# LPC18xx register map
File version: 18
Registers are 32-bit, read-write, reset 0x0 unless marked. A register's access mark holds for its fields unless they carry their own. Offsets are from the block's base; [hi:lo] are bit positions; 'fields as' and 'values as' point back to an identical list.

## I2S0 — Product name title=UM10430 Chapter title=LPC18xx I2S interface Modification date=1/14/2011 Major revision=0 Minor revision=7
Base 0x400A2000
Same registers: I2S1 0x400A3000
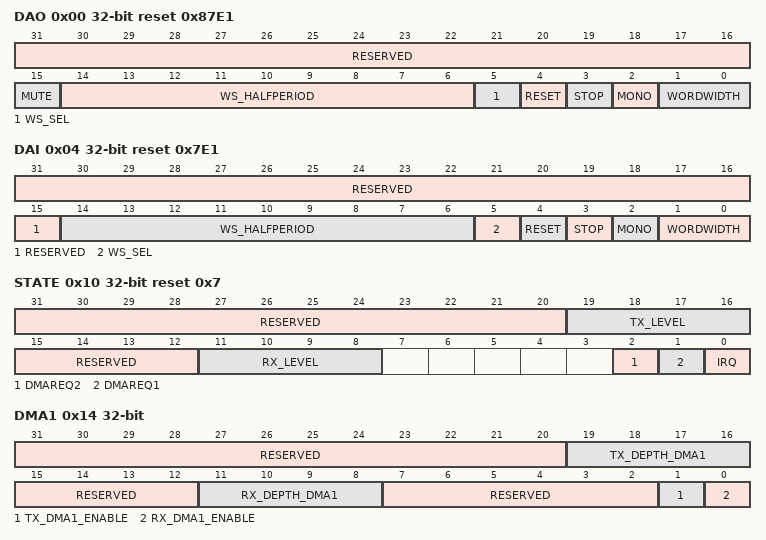
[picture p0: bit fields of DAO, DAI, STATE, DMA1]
0x00 DAO reset 0x87E1 — I2S Digital Audio Output Register. Contains control bits for the I2S transmit channel.
  [31:16] RESERVED — Reserved, user software should not write ones to reserved bits. The value read from a reserved bit is not defined.
  [15] MUTE — When 1, the transmit channel sends only zeroes.
  [14:6] WS_HALFPERIOD — Word select half period minus 1, i.e. WS 64clk period -> ws_halfperiod = 31.
  [5] WS_SEL — When 0, the interface is in master mode. When 1, the interface is in slave mode. See Section 34.7.2 for a summary of useful combinations for this bit with TXMODE.
  [4] RESET — When 1, asynchronously resets the transmit channel and FIFO.
  [3] STOP — When 1, disables accesses on FIFOs, places the transmit channel in mute mode.
  [2] MONO — When 1, data is of monaural format. When 0, the data is in stereo format.
  [1:0] WORDWIDTH — Selects the number of bytes in data as follows:
    0=8_BIT_DATA; 1=16_BIT_DATA; 2=RESERVED,_DO_NOT_USE (Reserved, do not use this setting); 3=32_BIT_DATA
0x04 DAI reset 0x7E1 — I2S Digital Audio Input Register. Contains control bits for the I2S receive channel.
  [31:15] RESERVED — Reserved, user software should not write ones to reserved bits. The value read from a reserved bit is not defined.
  [14:6] WS_HALFPERIOD — Word select half period minus 1, i.e. WS 64clk period -> ws_halfperiod = 31.
  [5] WS_SEL — When 0, the interface is in master mode. When 1, the interface is in slave mode. See Section 34.7.2 for a summary of useful combinations for this bit with RXMODE.
  [4] RESET — When 1, asynchronously reset the transmit channel and FIFO.
  [3] STOP — When 1, disables accesses on FIFOs, places the transmit channel in mute mode.
  [2] MONO — When 1, data is of monaural format. When 0, the data is in stereo format.
  [1:0] WORDWIDTH — Selects the number of bytes in data as follows:
    values as DAO.WORDWIDTH
0x08 TXFIFO wo — I2S Transmit FIFO. Access register for the 8 x 32-bit transmitter FIFO.
  [31:0] I2STXFIFO — 8 x 32-bit transmit FIFO.
0x0C RXFIFO ro — I2S Receive FIFO. Access register for the 8 x 32-bit receiver FIFO.
  [31:0] I2SRXFIFO — 8 x 32-bit transmit FIFO.
0x10 STATE ro reset 0x7 — I2S Status Feedback Register. Contains status information about the I2S interface.
  [31:20] RESERVED — Reserved, user software should not write ones to reserved bits. The value read from a reserved bit is not defined.
  [19:16] TX_LEVEL — Reflects the current level of the Transmit FIFO.
  [15:12] RESERVED — Reserved, user software should not write ones to reserved bits. The value read from a reserved bit is not defined.
  [11:8] RX_LEVEL — Reflects the current level of the Receive FIFO.
  [2] DMAREQ2 — This bit reflects the presence of Receive or Transmit DMA Request 2. This is determined by comparing the current FIFO levels to the rx_depth_dma2 and tx_depth_dma2 fields in the DMA2 register.
  [1] DMAREQ1 — This bit reflects the presence of Receive or Transmit DMA Request 1. This is determined by comparing the current FIFO levels to the rx_depth_dma1 and tx_depth_dma1 fields in the DMA1 register.
  [0] IRQ — This bit reflects the presence of Receive Interrupt or Transmit Interrupt. This is determined by comparing the current FIFO levels to the rx_depth_irq and tx_depth_irq fields in the IRQ register.
0x14 DMA1 — I2S DMA Configuration Register 1. Contains control information for DMA request 1.
  [31:20] RESERVED — Reserved, user software should not write ones to reserved bits. The value read from a reserved bit is not defined.
  [19:16] TX_DEPTH_DMA1 — Set the FIFO level that triggers a transmit DMA request on DMA1.
  [15:12] RESERVED — Reserved, user software should not write ones to reserved bits. The value read from a reserved bit is not defined.
  [11:8] RX_DEPTH_DMA1 — Set the FIFO level that triggers a receive DMA request on DMA1.
  [7:2] RESERVED — Reserved, user software should not write ones to reserved bits. The value read from a reserved bit is not defined.
  [1] TX_DMA1_ENABLE — When 1, enables DMA1 for I2S transmit.
  [0] RX_DMA1_ENABLE — When 1, enables DMA1 for I2S receive.
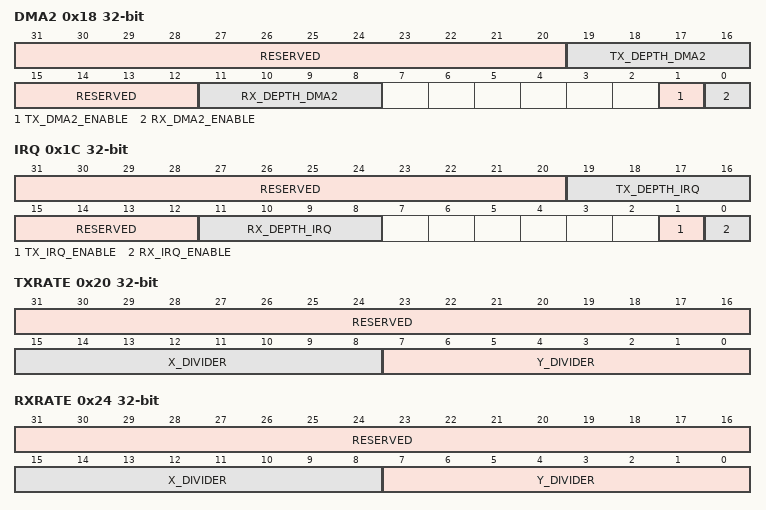
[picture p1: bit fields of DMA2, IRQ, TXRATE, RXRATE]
0x18 DMA2 — I2S DMA Configuration Register 2. Contains control information for DMA request 2.
  [31:20] RESERVED — Reserved, user software should not write ones to reserved bits. The value read from a reserved bit is not defined.
  [19:16] TX_DEPTH_DMA2 — Set the FIFO level that triggers a transmit DMA request on DMA2.
  [15:12] RESERVED — Reserved, user software should not write ones to reserved bits. The value read from a reserved bit is not defined.
  [11:8] RX_DEPTH_DMA2 — Set the FIFO level that triggers a receive DMA request on DMA2.
  [1] TX_DMA2_ENABLE — When 1, enables DMA1 for I2S transmit.
  [0] RX_DMA2_ENABLE — When 1, enables DMA1 for I2S receive.
0x1C IRQ — I2S Interrupt Request Control Register. Contains bits that control how the I2S interrupt request is generated.
  [31:20] RESERVED — Reserved, user software should not write ones to reserved bits. The value read from a reserved bit is not defined.
  [19:16] TX_DEPTH_IRQ — Set the FIFO level on which to create an irq request.
  [15:12] RESERVED — Reserved, user software should not write ones to reserved bits. The value read from a reserved bit is not defined.
  [11:8] RX_DEPTH_IRQ — Set the FIFO level on which to create an irq request.
  [1] TX_IRQ_ENABLE — When 1, enables I2S transmit interrupt.
  [0] RX_IRQ_ENABLE — When 1, enables I2S receive interrupt.
0x20 TXRATE — I2S Transmit MCLK divider. This register determines the I2S TX MCLK rate by specifying the value to divide PCLK by in order to produce MCLK.
  [31:16] RESERVED — Reserved, user software should not write ones to reserved bits. The value read from a reserved bit is not defined.
  [15:8] X_DIVIDER — I2S transmit MCLK rate numerator. This value is used to multiply PCLK by to produce the transmit MCLK. A value of 0 stops the clock. Eight bits of fractional divide supports a wide range of possibilities. Note: the resulting ratio X/Y is divided by 2.
  [7:0] Y_DIVIDER — I2S transmit MCLK rate denominator. This value is used to divide PCLK to produce the transmit MCLK. Eight bits of fractional divide supports a wide range of possibilities. A value of 0 stops the clock.
0x24 RXRATE — I2S Receive MCLK divider. This register determines the I2S RX MCLK rate by specifying the value to divide PCLK by in order to produce MCLK.
  [31:16] RESERVED — Reserved, user software should not write ones to reserved bits. The value read from a reserved bit is not defined.
  [15:8] X_DIVIDER — I2S receive MCLK rate numerator. This value is used to multiply PCLK by to produce the receive MCLK. A value of 0 stops the clock. Eight bits of fractional divide supports a wide range of possibilities. Note: the resulting ratio X/Y is divided by 2.
  [7:0] Y_DIVIDER — I2S receive MCLK rate denominator. This value is used to divide PCLK to produce the receive MCLK. Eight bits of fractional divide supports a wide range of possibilities. A value of 0 stops the clock.
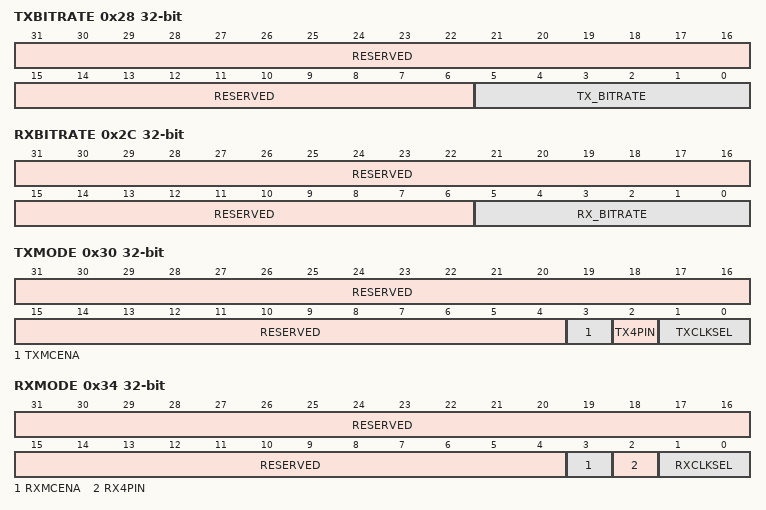
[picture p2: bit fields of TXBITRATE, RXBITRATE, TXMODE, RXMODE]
0x28 TXBITRATE — I2S Transmit bit rate divider. This register determines the I2S transmit bit rate by specifying the value to divide TX_MCLK by in order to produce the transmit bit clock.
  [31:6] RESERVED — Reserved, user software should not write ones to reserved bits. The value read from a reserved bit is not defined.
  [5:0] TX_BITRATE — I2S transmit bit rate. This value plus one is used to divide TX_MCLK to produce the transmit bit clock.
0x2C RXBITRATE — I2S Receive bit rate divider. This register determines the I2S receive bit rate by specifying the value to divide RX_MCLK by in order to produce the receive bit clock.
  [31:6] RESERVED — Reserved, user software should not write ones to reserved bits. The value read from a reserved bit is not defined.
  [5:0] RX_BITRATE — I2S receive bit rate. This value plus one is used to divide RX_MCLK to produce the receive bit clock.
0x30 TXMODE — I2S Transmit mode control.
  [31:4] RESERVED — Reserved, user software should not write ones to reserved bits. The value read from a reserved bit is not defined.
  [3] TXMCENA — Enable for the TX_MCLK output. When 0, output of TX_MCLK is not enabled. When 1, output of TX_MCLK is enabled.
  [2] TX4PIN — Transmit 4-pin mode selection. When 1, enables 4-pin mode.
  [1:0] TXCLKSEL — Clock source selection for the transmit bit clock divider.
    0=SELECT_THE_TX_FRACTI (Select the TX fractional rate divider clock output as the source); 2=SELECT_THE_RX_MCLK_S (Select the RX_MCLK signal as the TX_MCLK clock source)
0x34 RXMODE — I2S Receive mode control.
  [31:4] RESERVED — Reserved, user software should not write ones to reserved bits. The value read from a reserved bit is not defined.
  [3] RXMCENA — Enable for the RX_MCLK output. When 0, output of RX_MCLK is not enabled. When 1, output of RX_MCLK is enabled.
  [2] RX4PIN — Receive 4-pin mode selection. When 1, enables 4-pin mode.
  [1:0] RXCLKSEL — Clock source selection for the receive bit clock divider.
    0=SELECT_THE_RX_FRACTI (Select the RX fractional rate divider clock output as the source); 2=SELECT_THE_TX_MCLK_S (Select the TX_MCLK signal as the RX_MCLK clock source)
